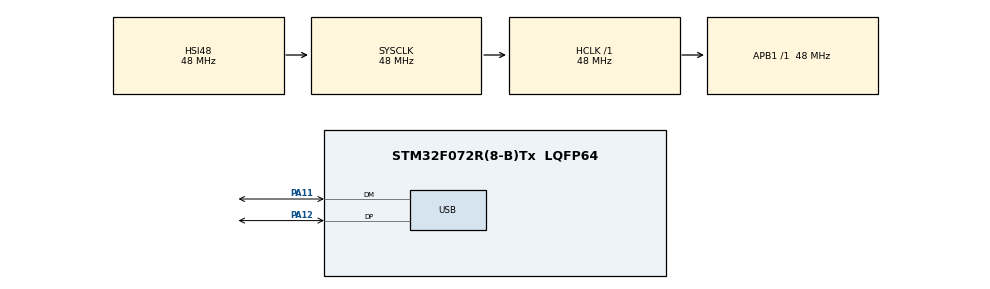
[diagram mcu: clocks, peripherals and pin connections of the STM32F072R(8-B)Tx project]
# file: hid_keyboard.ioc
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Mcu.Family=STM32F0
Mcu.Name=STM32F072R(8-B)Tx
Mcu.Package=LQFP64
NVIC.USB_IRQn=true\:0\:0\:false
PA11.Mode=Device
PA11.Signal=USB_DM
PA12.Mode=Device
PA12.Signal=USB_DP
PA13.Mode=Serial-WireDebug
PA13.Signal=SYS_SWDIO
PA14.Mode=Serial-WireDebug
PA14.Signal=SYS_SWCLK
ProjectManager.TargetToolchain=MDK-ARM V5
RCC.AHBFreq_Value=48000000
RCC.APB1Freq_Value=48000000
RCC.APB1TimFreq_Value=48000000
RCC.HCLKFreq_Value=48000000
RCC.SYSCLKFreq_VALUE=48000000
RCC.SYSCLKSource=RCC_SYSCLKSOURCE_HSI48
USB_DEVICE.USBD_HandleTypeDef=hUsbDeviceFS
USB_DEVICE.VirtualMode=Hid
USB_DEVICE.VirtualModeFS=Hid_FS
VP_USB_DEVICE_VS_USB_DEVICE_HID_FS.Mode=HID_FS
board=hid_keyboard

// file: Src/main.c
/**
  ******************************************************************************
  * File Name          : main.c
  * Description        : Main program body
  ******************************************************************************
  *
  * COPYRIGHT(c) 2016 STMicroelectronics
  *
  * Redistribution and use in source and binary forms, with or without modification,
  * are permitted provided that the following conditions are met:
  *   1. Redistributions of source code must retain the above copyright notice,
  *      this list of conditions and the following disclaimer.
  *   2. Redistributions in binary form must reproduce the above copyright notice,
  *      this list of conditions and the following disclaimer in the documentation
  *      and/or other materials provided with the distribution.
  *   3. Neither the name of STMicroelectronics nor the names of its contributors
  *      may be used to endorse or promote products derived from this software
  *      without specific prior written permission.
  *
  * THIS SOFTWARE IS PROVIDED BY THE COPYRIGHT HOLDERS AND CONTRIBUTORS "AS IS"
  * AND ANY EXPRESS OR IMPLIED WARRANTIES, INCLUDING, BUT NOT LIMITED TO, THE
  * IMPLIED WARRANTIES OF MERCHANTABILITY AND FITNESS FOR A PARTICULAR PURPOSE ARE
  * DISCLAIMED. IN NO EVENT SHALL THE COPYRIGHT HOLDER OR CONTRIBUTORS BE LIABLE
  * FOR ANY DIRECT, INDIRECT, INCIDENTAL, SPECIAL, EXEMPLARY, OR CONSEQUENTIAL
  * DAMAGES (INCLUDING, BUT NOT LIMITED TO, PROCUREMENT OF SUBSTITUTE GOODS OR
  * SERVICES; LOSS OF USE, DATA, OR PROFITS; OR BUSINESS INTERRUPTION) HOWEVER
  * CAUSED AND ON ANY THEORY OF LIABILITY, WHETHER IN CONTRACT, STRICT LIABILITY,
  * OR TORT (INCLUDING NEGLIGENCE OR OTHERWISE) ARISING IN ANY WAY OUT OF THE USE
  * OF THIS SOFTWARE, EVEN IF ADVISED OF THE POSSIBILITY OF SUCH DAMAGE.
  *
  ******************************************************************************
  */
#include "stm32f0xx_hal.h"
#include "usb_device.h"

/* USER CODE BEGIN Includes */
#include "usbd_hid.h"
extern USBD_HandleTypeDef hUsbDeviceFS;
/* USER CODE END Includes */

/* USER CODE BEGIN PV */
/* Private variables ---------------------------------------------------------*/
uint8_t buffer[8];
/* USER CODE END PV */

void SystemClock_Config(void);
static void MX_GPIO_Init(void);

/* USER CODE BEGIN PFP */
/* Private function prototypes -----------------------------------------------*/

/* USER CODE END PFP */

int main(void)
{

  /* MCU Configuration----------------------------------------------------------*/

  /* Reset of all peripherals, Initializes the Flash interface and the Systick. */
  HAL_Init();

  /* Configure the system clock */
  SystemClock_Config();

  /* Initialize all configured peripherals */
  MX_GPIO_Init();
  MX_USB_DEVICE_Init();

  /* Infinite loop */
  while (1)
  {
///////////////////////HelloWorld////////////////////////////
		buffer[2] = 0x0B;//h
		USBD_HID_SendReport(&hUsbDeviceFS, buffer, 8);
		HAL_Delay(40);
		buffer[2] = 0x00;
		USBD_HID_SendReport(&hUsbDeviceFS, buffer, 8);
		HAL_Delay(1000);
/////////////////////////////////////////////////////////////
		buffer[2] = 0x08;//e
		USBD_HID_SendReport(&hUsbDeviceFS, buffer, 8);
		HAL_Delay(40);
		buffer[2] = 0x00;
		USBD_HID_SendReport(&hUsbDeviceFS, buffer, 8);
		HAL_Delay(1000);
////////////////////////////////////////////////////////////
		buffer[2] = 0x0F;//l
		USBD_HID_SendReport(&hUsbDeviceFS, buffer, 8);
		HAL_Delay(40);
		buffer[2] = 0x00;
		USBD_HID_SendReport(&hUsbDeviceFS, buffer, 8);
		HAL_Delay(1000);
////////////////////////////////////////////////////////////
		buffer[2] = 0x0F;//l
		USBD_HID_SendReport(&hUsbDeviceFS, buffer, 8);
		HAL_Delay(40);
		buffer[2] = 0x00;
		USBD_HID_SendReport(&hUsbDeviceFS, buffer, 8);
		HAL_Delay(1000);
////////////////////////////////////////////////////////////
		buffer[2] = 0x12;//o
		USBD_HID_SendReport(&hUsbDeviceFS, buffer, 8);
		HAL_Delay(40);
		buffer[2] = 0x00;
		USBD_HID_SendReport(&hUsbDeviceFS, buffer, 8);
		HAL_Delay(1000);
////////////////////////////////////////////////////////////
		buffer[2] = 0x2C;//space
		USBD_HID_SendReport(&hUsbDeviceFS, buffer, 8);
		HAL_Delay(40);
		buffer[2] = 0x00;
		USBD_HID_SendReport(&hUsbDeviceFS, buffer, 8);
		HAL_Delay(1000);
////////////////////////////////////////////////////////////
		buffer[2] = 0x1A;//w
		USBD_HID_SendReport(&hUsbDeviceFS, buffer, 8);
		HAL_Delay(40);
		buffer[2] = 0x00;
		USBD_HID_SendReport(&hUsbDeviceFS, buffer, 8);
		HAL_Delay(1000);
////////////////////////////////////////////////////////////
		buffer[2] = 0x12;//o
		USBD_HID_SendReport(&hUsbDeviceFS, buffer, 8);
		HAL_Delay(40);
		buffer[2] = 0x00;
		USBD_HID_SendReport(&hUsbDeviceFS, buffer, 8);
		HAL_Delay(1000);
////////////////////////////////////////////////////////////
		buffer[2] = 0x15;//r
		USBD_HID_SendReport(&hUsbDeviceFS, buffer, 8);
		HAL_Delay(40);
		buffer[2] = 0x00;
		USBD_HID_SendReport(&hUsbDeviceFS, buffer, 8);
		HAL_Delay(1000);
////////////////////////////////////////////////////////////
		buffer[2] = 0x0F;//l
		USBD_HID_SendReport(&hUsbDeviceFS, buffer, 8);
		HAL_Delay(40);
		buffer[2] = 0x00;
		USBD_HID_SendReport(&hUsbDeviceFS, buffer, 8);
		HAL_Delay(1000);
////////////////////////////////////////////////////////////
		buffer[2] = 0x07;//d
		USBD_HID_SendReport(&hUsbDeviceFS, buffer, 8);
		HAL_Delay(40);
		for(uint8_t i=0;i <= 7;i++){
		buffer[i] = 0x00;
		}//
		USBD_HID_SendReport(&hUsbDeviceFS, buffer, 8);
		HAL_Delay(1000);
////////////////////////////////////////////////////////////
		buffer[2] = 0x28;//enter
		USBD_HID_SendReport(&hUsbDeviceFS, buffer, 8);
		HAL_Delay(500);//!important
		for(uint8_t i=0;i <= 7;i++){
		buffer[i] = 0x00;
		}
USBD_HID_SendReport(&hUsbDeviceFS, buffer, 8);
		HAL_Delay(1000);
  }

}

/** System Clock Configuration
*/
void SystemClock_Config(void)
{

  RCC_OscInitTypeDef RCC_OscInitStruct;
  RCC_ClkInitTypeDef RCC_ClkInitStruct;
  RCC_PeriphCLKInitTypeDef PeriphClkInit;

  RCC_OscInitStruct.OscillatorType = RCC_OSCILLATORTYPE_HSI48;
  RCC_OscInitStruct.HSI48State = RCC_HSI48_ON;
  RCC_OscInitStruct.PLL.PLLState = RCC_PLL_NONE;
  HAL_RCC_OscConfig(&RCC_OscInitStruct);

  RCC_ClkInitStruct.ClockType = RCC_CLOCKTYPE_SYSCLK;
  RCC_ClkInitStruct.SYSCLKSource = RCC_SYSCLKSOURCE_HSI48;
  RCC_ClkInitStruct.AHBCLKDivider = RCC_SYSCLK_DIV1;
  RCC_ClkInitStruct.APB1CLKDivider = RCC_HCLK_DIV1;
  HAL_RCC_ClockConfig(&RCC_ClkInitStruct, FLASH_LATENCY_1);

  PeriphClkInit.PeriphClockSelection = RCC_PERIPHCLK_USB;
  PeriphClkInit.UsbClockSelection = RCC_USBCLKSOURCE_HSI48;
  HAL_RCCEx_PeriphCLKConfig(&PeriphClkInit);

  HAL_SYSTICK_Config(HAL_RCC_GetHCLKFreq()/1000);

  HAL_SYSTICK_CLKSourceConfig(SYSTICK_CLKSOURCE_HCLK);

  /* SysTick_IRQn interrupt configuration */
  HAL_NVIC_SetPriority(SysTick_IRQn, 0, 0);
}

/** Configure pins as
        * Analog
        * Input
        * Output
        * EVENT_OUT
        * EXTI
*/
void MX_GPIO_Init(void)
{

  /* GPIO Ports Clock Enable */
  __GPIOA_CLK_ENABLE();

}

/************************ (C) COPYRIGHT STMicroelectronics *****END OF FILE****/
